AUTOSAR XML (schema 00044)
package /ComponentTypes
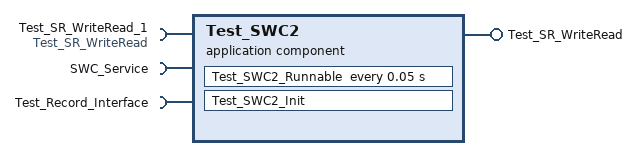
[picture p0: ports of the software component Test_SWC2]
  application sw component type Test_SWC2
    provide port Test_SR_WriteRead: provided-com-specs=[{data-element=DataElement1, init-value=0}, {data-element=DataElement2, init-value=12}], provided-interface=Test_SR_WriteRead
    require port Test_SR_WriteRead_1: required-interface=Test_SR_WriteRead
      required-com-specs:
        data-element=DataElement1, init-value=0
        data-element=DataElement2, filter=data-filter-type=ALWAYS, init-value=11
    require port SWC_Service: client-com-spec=testService, required-interface=SWC_Service
    require port Test_Record_Interface: nonqueued-receiver-com-spec=data-element=Record, required-interface=Test_Record_Interface
    behavior Test_SWC2_InternalBehavior
      init event Test_SWC2_InitEvent: start-on-event=Test_SWC2_Init
      timing event TMT_Test_SWC2_Runnable: start-on-event=Test_SWC2_Runnable, period=0.05
      runnable Test_SWC2_Init
        data-receive-point-by-arguments:
          access REC_Test_SR_WriteRead_1_DataElement1: accessed-variable=Test_SR_WriteRead_1.DataElement1
        data-send-points:
          access SEND_Test_SR_WriteRead_DataElement1: accessed-variable=Test_SR_WriteRead.DataElement1
      runnable Test_SWC2_Runnable: minimum-start-interval=0.05
        data-receive-point-by-arguments:
          access REC_Test_SR_WriteRead_1_DataElement1: accessed-variable=Test_SR_WriteRead_1.DataElement1
          access REC_Test_SR_WriteRead_1_DataElement2: accessed-variable=Test_SR_WriteRead_1.DataElement2
          access REC_Test_Record_Interface_Record: accessed-variable=Test_Record_Interface.Record
        data-send-points:
          access SEND_Test_SR_WriteRead_DataElement1: accessed-variable=Test_SR_WriteRead.DataElement1
          access SEND_Test_SR_WriteRead_DataElement2: accessed-variable=Test_SR_WriteRead.DataElement2
        sync call SC_SWC_Service_testService: operation=SWC_Service.testService
  swc implementation Test_SWC2_Implementation: behavior=Test_SWC2_InternalBehavior
